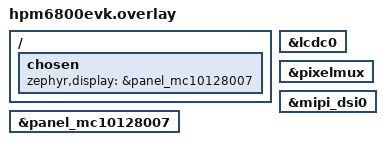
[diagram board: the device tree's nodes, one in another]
/*
* Copyright 2024-2026 HPMicro
* SPDX-License-Identifier: Apache-2.0
*/

/ {
	chosen {
		zephyr,display = &panel_mc10128007;
	};
};

&lcdc0 {
	status = "okay";
};

&pixelmux {
	status = "okay";
};

&mipi_dsi0 {
	status = "okay";
};

&panel_mc10128007 {
	status = "okay";
};
